# RZ/A1H register map
Vendor: Renesas
Registers are 32-bit, read-write, reset 0x0 unless marked. A register's access mark holds for its fields unless they carry their own. Offsets are from the block's base; [hi:lo] are bit positions; {n}, {i} and the like mark numbered series.

## DVDEC1
Base 0xFCFFA008
Same registers: DVDEC0 0xFCFFB808
0x00 ADCCR1 16-bit
{0x4+2i} TGCR{i} 16-bit (i=1..3)
{0x10+2i} SYNSCR{i} 16-bit (i=1..5)
{0x1A+2i} HAFCCR{i} 16-bit (i=1..3)
0x22 VCDWCR1 16-bit
{0x26+2i} DCPCR{i} 16-bit (i=1..8)
0x38 NSDCR 16-bit
0x3A BTLCR 16-bit
0x3C BTGPCR 16-bit
{0x3C+2i} ACCCR{i} 16-bit (i=1..3)
0x44 TINTCR 16-bit
0x46 YCDCR 16-bit
0x48 AGCCR1 16-bit
0x4A AGCCR2 16-bit
0x4C PKLIMITCR 16-bit
{0x4C+2i} RGORCR{i} 16-bit (i=1..7)
0x74 AFCPFCR 16-bit
0x76 RUPDCR 16-bit
0x78 VSYNCSR 16-bit
0x7A HSYNCSR 16-bit
0x7C DCPSR1 16-bit
0x7E DCPSR2 16-bit
0x84 NSDSR 16-bit
0x86 CROMASR1 16-bit
0x88 CROMASR2 16-bit
0x8A SYNCSSR 16-bit
0x8C AGCCSR1 16-bit
0x8E AGCCSR2 16-bit
{0xF6+2i} YCSCR{i} 16-bit (i=3..9)
0x10C YCSCR11 16-bit
0x10E YCSCR12 16-bit
0x178 DCPCR9 16-bit
{0x18A+2i} YCTWA_F{i} 16-bit (i=0..8)
{0x19C+2i} YCTWB_F{i} 16-bit (i=0..8)
{0x1AE+2i} YCTNA_F{i} 16-bit (i=0..8)
{0x1C0+2i} YCTNB_F{i} 16-bit (i=0..8)
0x1F8 YGAINCR 16-bit
0x1FA CBGAINCR 16-bit
0x1FC CRGAINCR 16-bit
0x278 PGA_UPDATE 16-bit
0x27A PGACR 16-bit
0x27C ADCCR2 16-bit

## ETHER
Base 0xE8203000
0x00 EDSR0
0x10 TDLAR0
0x14 TDFAR0
0x18 TDFXR0
0x1C TDFFR0
0x30 RDLAR0
0x34 RDFAR0
0x38 RDFXR0
0x3C RDFFR0
0x400 EDMR0
0x408 EDTRR0
0x410 EDRRR0
0x428 EESR0
0x430 EESIPR0
0x438 TRSCER0
0x440 RMFCR0
0x448 TFTR0
0x450 FDR0
0x458 RMCR0
0x460 RPADIR0
0x468 FCFTR0
0x4E4 CSMR
0x4E8 CSSBM
0x4EC CSSMR
0x500 ECMR0
0x508 RFLR0
0x510 ECSR0
0x518 ECSIPR0
0x520 PIR0
0x554 APR0
0x558 MPR0
0x55C PFTCR0
0x560 PFRCR0
0x564 TPAUSER0
0x5C0 MAHR0
0x5C8 MALR0
0x740 CEFCR0
0x748 FRECR0
0x750 TSFRCR0
0x758 TLFRCR0
0x760 RFCR0
0x778 MAFCR0
0x1800 ARSTR
0x1804 TSU_CTRST
0x1858 TSU_VTAG0
0x1860 TSU_ADSBSY
0x1864 TSU_TEN
0x1880 TXNLCR0
0x1884 TXALCR0
0x1888 RXNLCR0
0x188C RXALCR0
{0x1900+8i} TSU_ADRH{i} (i=0..31)
{0x1904+8i} TSU_ADRL{i} (i=0..31)

## FLCTL
Base 0xFCFF4000
0x00 FLCMNCR
0x04 FLCMDCR
0x08 FLCMCDR
0x0C FLADR
0x10 FLDATAR
0x14 FLDTCNTR
0x18 FLINTDMACR
0x1C FLBSYTMR
0x20 FLBSYCNT
0x2C FLTRCR 8-bit
0x3C FLADR2
0x50 FLDTFIFO

## IEB
Base 0xFCFEF000
0x00 B0BCR 8-bit
0x04 B0PSR 8-bit
0x08 B0UAR 16-bit
0x0C B0SAR 16-bit
0x10 B0PAR 16-bit
0x14 B0RSA 16-bit
0x18 B0CDR 8-bit
0x1C B0TCD 8-bit
0x20 B0RCD 8-bit
0x24 B0DLR 8-bit
0x28 B0TDL 8-bit
0x2C B0RDL 8-bit
0x30 B0CKS 8-bit
0x34 B0TMS 8-bit
0x38 B0PCR 8-bit
0x3C B0BSR 16-bit
0x40 B0SSR 8-bit
0x44 B0USR 8-bit
0x48 B0ISR 8-bit
0x4C B0ESR 8-bit
0x50 B0FSR 8-bit
0x54 B0SCR 8-bit
0x58 B0CCR 8-bit
0x5C B0STC0 8-bit
0x60 B0STC1 8-bit
0x64 B0DR 8-bit

## INB
Base 0xFCFE1A00
0x00 RMPR
{0x4+4i} AXIBUSCTL{i} (i=0..10)
{0x30+4i} AXIRERRCTL{i} (i=0..3)
{0x40+4i} AXIRERRST{i} (i=0..3)
{0x50+4i} AXIRERRCLR{i} (i=0..3)

## IRDA
Base 0xE8014000
0x00 IRCR 8-bit

## JCU
Base 0xE8017000
0x00 JCMOD 8-bit
  [7] BRST, [3] DSP, [2] JEND, [1] JRST, [2:0] REDU, [0] JSRT
0x01 JCCMD 8-bit
  [7] BRST, [3] DSP, [2] JEND, [1] JRST, [2:0] REDU, [0] JSRT
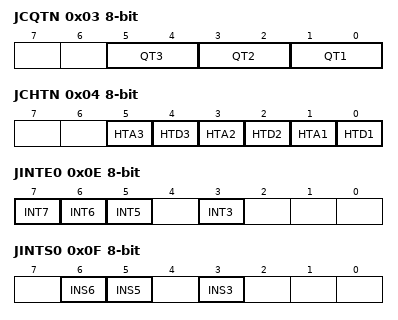
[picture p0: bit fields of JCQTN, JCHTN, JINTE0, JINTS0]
0x03 JCQTN 8-bit
  [5:4] QT3, [3:2] QT2, [1:0] QT1
0x04 JCHTN 8-bit
  [5] HTA3, [4] HTD3, [3] HTA2, [2] HTD2, [1] HTA1, [0] HTD1
0x05 JCDRIU 8-bit
0x06 JCDRID 8-bit
0x07 JCVSZU 8-bit
0x08 JCVSZD 8-bit
0x09 JCHSZU 8-bit
0x0A JCHSZD 8-bit
0x0B JCDTCU 8-bit
0x0C JCDTCM 8-bit
0x0D JCDTCD 8-bit
0x0E JINTE0 8-bit
  [7] INT7, [6] INT6, [5] INT5, [3] INT3
0x0F JINTS0 8-bit
  [6] INS6, [5] INS5, [3] INS3
0x10 JCDERR 8-bit
  [3:0] ERR
0x11 JCRST 8-bit
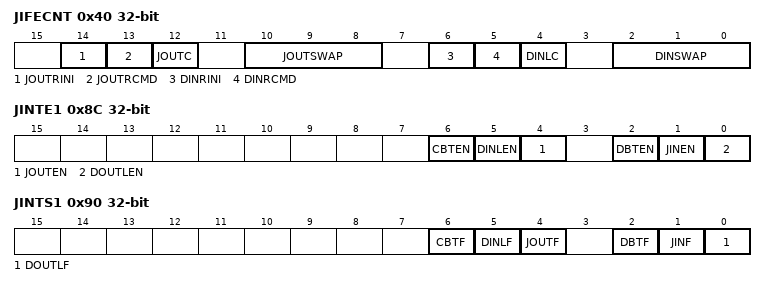
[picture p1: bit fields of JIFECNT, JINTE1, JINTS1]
0x40 JIFECNT
  [14] JOUTRINI, [13] JOUTRCMD, [12] JOUTC, [10:8] JOUTSWAP, [6] DINRINI, [5] DINRCMD, [4] DINLC, [2:0] DINSWAP
0x44 JIFESA
0x48 JIFESOFST
  [14:0] ESMW
0x4C JIFEDA
0x50 JIFESLC
  [15:0] LINES, [15:0] JDATAS
0x54 JIFEDDC
  [15:0] JDATAS
0x58 JIFDCNT
  [29:26] VINTER, [27:26] HINTER, [25:24] OPF, [14] JINRINI, [13] JINRCMD, [12] JINC, [10:8] JINSWAP, [6] DOUTRINI, [5] DOUTRCMD, [4] DOUTLC, [2:0] DOUTSWAP
0x5C JIFDSA
0x60 JIFDDOFST
  [14:0] DDMW
0x64 JIFDDA
0x68 JIFDSDC
  [15:0] JDATAS
0x6C JIFDDLC
  [15:0] LINES
0x70 JIFDADT
  [7:0] ALPHA
0x8C JINTE1
  [6] CBTEN, [5] DINLEN, [4] JOUTEN, [2] DBTEN, [1] JINEN, [0] DOUTLEN
0x90 JINTS1
  [6] CBTF, [5] DINLF, [4] JOUTF, [2] DBTF, [1] JINF, [0] DOUTLF
0x94 JIFESVSZ
  [15] DINYCHG
0x98 JIFESHSZ
  [15] DOUTYCHG
{0x100+0x40*i} JCQTBL{i} 8-bit (i=0..3)
0x200 JCHTBD0 8-bit
0x220 JCHTBA0 8-bit
0x300 JCHTBD1 8-bit
0x320 JCHTBA1 8-bit
